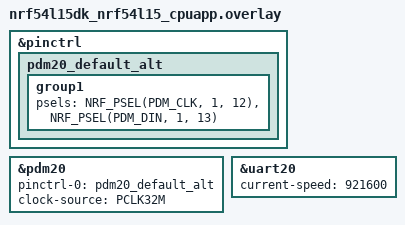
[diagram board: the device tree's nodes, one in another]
/*
 * Copyright (c) 2025 Nordic Semiconductor ASA
 *
 * SPDX-License-Identifier: LicenseRef-Nordic-5-Clause
 */

&pinctrl {
	pdm20_default_alt: pdm20_default_alt {
		group1 {
			psels = <NRF_PSEL(PDM_CLK, 1, 12)>,
				<NRF_PSEL(PDM_DIN, 1, 13)>;
		};
	};
};

dmic_dev: &pdm20 {
	status = "okay";
	pinctrl-0 = <&pdm20_default_alt>;
	pinctrl-names = "default";
	clock-source = "PCLK32M";
};

&uart20 {
	current-speed = <921600>;
};
